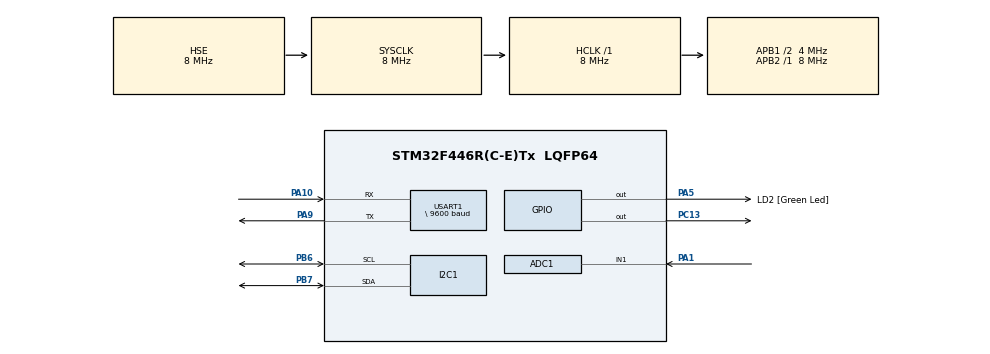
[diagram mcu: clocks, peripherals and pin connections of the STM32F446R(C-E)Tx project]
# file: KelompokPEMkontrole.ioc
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ADC1.Channel-0\#ChannelRegularConversion=ADC_CHANNEL_1
ADC1.NbrOfConversionFlag=1
ADC1.Rank-0\#ChannelRegularConversion=1
ADC1.SamplingTime-0\#ChannelRegularConversion=ADC_SAMPLETIME_3CYCLES
ADC1.master=1
FREERTOS.Tasks01=defaultTask,0,128,StartDefaultTask,Default,NULL,Dynamic,NULL,NULL;ReadPMTask,-2,128,StartTask02,Default,NULL,Dynamic,NULL,NULL;ReadMQTask,-2,128,StartTask03,Default,NULL,Dynamic,NULL,NULL;DisplayTask,0,128,StartTask04,Default,NULL,Dynamic,NULL,NULL
IWDG.Prescaler=IWDG_PRESCALER_64
Mcu.Family=STM32F4
Mcu.Name=STM32F446R(C-E)Tx
Mcu.Package=LQFP64
NVIC.PriorityGroup=NVIC_PRIORITYGROUP_4
NVIC.TIM2_IRQn=true\:15\:0\:false\:false\:true\:false\:false\:true\:true
NVIC.TimeBase=TIM2_IRQn
NVIC.TimeBaseIP=TIM2
PA1.Signal=ADCx_IN1
PA10.Mode=Asynchronous
PA10.Signal=USART1_RX
PA13.GPIO_Label=TMS
PA13.Mode=Serial_Wire
PA13.Signal=SYS_JTMS-SWDIO
PA14.GPIO_Label=TCK
PA14.Mode=Serial_Wire
PA14.Signal=SYS_JTCK-SWCLK
PA2.GPIO_Label=USART_TX
PA2.Signal=USART2_TX
PA3.GPIO_Label=USART_RX
PA3.Signal=USART2_RX
PA5.GPIO_Label=LD2 [Green Led]
PA5.Signal=GPIO_Output
PA9.Mode=Asynchronous
PA9.Signal=USART1_TX
PB3.GPIO_Label=SWO
PB3.Signal=SYS_JTDO-SWO
PB6.Mode=I2C
PB6.Signal=I2C1_SCL
PB7.Mode=I2C
PB7.Signal=I2C1_SDA
PC13.Signal=GPIO_Output
PC14-OSC32_IN.Mode=LSE-External-Oscillator
PC14-OSC32_IN.Signal=RCC_OSC32_IN
PC15-OSC32_OUT.Mode=LSE-External-Oscillator
PC15-OSC32_OUT.Signal=RCC_OSC32_OUT
PH0-OSC_IN.Mode=HSE-External-Oscillator
PH0-OSC_IN.Signal=RCC_OSC_IN
PH1-OSC_OUT.Mode=HSE-External-Oscillator
PH1-OSC_OUT.Signal=RCC_OSC_OUT
ProjectManager.HeapSize=0x200
ProjectManager.StackSize=0x400
ProjectManager.TargetToolchain=MDK-ARM V5.32
RCC.48MHZClocksFreq_Value=84000000
RCC.AHBFreq_Value=8000000
RCC.APB1CLKDivider=RCC_HCLK_DIV2
RCC.APB1Freq_Value=4000000
RCC.APB1TimFreq_Value=8000000
RCC.APB2Freq_Value=8000000
RCC.APB2TimFreq_Value=8000000
RCC.CortexFreq_Value=8000000
RCC.FLatency-AdvancedSettings=FLASH_LATENCY_0
RCC.HCLKFreq_Value=8000000
RCC.HSE_VALUE=8000000
RCC.HSI_VALUE=16000000
RCC.PLLM=4
RCC.PLLN=72
RCC.PLLSourceVirtual=RCC_PLLSOURCE_HSE
RCC.SYSCLKFreq_VALUE=8000000
RCC.SYSCLKSource=RCC_SYSCLKSOURCE_HSE
RCC.USBFreq_Value=72000000
RCC.VCOOutputFreq_Value=144000000
SH.ADCx_IN1.0=ADC1_IN1,IN1
TIM1.Prescaler=71
USART1.BaudRate=\ 9600
USART1.VirtualMode=VM_ASYNC
VP_FREERTOS_VS_CMSIS_V1.Mode=CMSIS_V1
VP_IWDG_VS_IWDG.Mode=IWDG_Activate
VP_SYS_VS_tim2.Mode=TIM2
VP_TIM1_VS_ClockSourceINT.Mode=Internal
board=NUCLEO-F446RE

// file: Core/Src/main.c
/* USER CODE BEGIN Header */
/**
  ******************************************************************************
  * @file           : main.c
  * @brief          : Main program body
  ******************************************************************************
  * @attention
  *
  * Copyright (c) 2025 STMicroelectronics.
  * All rights reserved.
  *
  * This software is licensed under terms that can be found in the LICENSE file
  * in the root directory of this software component.
  * If no LICENSE file comes with this software, it is provided AS-IS.
  *
  ******************************************************************************
  */
/* USER CODE END Header */
#include "main.h"
#include "cmsis_os.h"

/* USER CODE BEGIN Includes */
#include "pm25sensor.h"
#include "mq135_sensor.h"
#include "display1.h"
#include <string.h>
/* USER CODE END Includes */

ADC_HandleTypeDef hadc1;

I2C_HandleTypeDef hi2c1;

IWDG_HandleTypeDef hiwdg;

TIM_HandleTypeDef htim1;

UART_HandleTypeDef huart1;

osThreadId defaultTaskHandle;
osThreadId ReadPMTaskHandle;
osThreadId ReadMQTaskHandle;
osThreadId DisplayTaskHandle;

void SystemClock_Config(void);
static void MX_GPIO_Init(void);
static void MX_ADC1_Init(void);
static void MX_I2C1_Init(void);
static void MX_USART1_UART_Init(void);
static void MX_TIM1_Init(void);
static void MX_IWDG_Init(void);
void StartDefaultTask(void const * argument);
void StartTask02(void const * argument);
void StartTask03(void const * argument);
void StartTask04(void const * argument);

int main(void)
{

  /* MCU Configuration--------------------------------------------------------*/

  /* Reset of all peripherals, Initializes the Flash interface and the Systick. */
  HAL_Init();

  /* Configure the system clock */
  SystemClock_Config();

  /* Initialize all configured peripherals */
  MX_GPIO_Init();
  MX_ADC1_Init();
  MX_I2C1_Init();
  MX_USART1_UART_Init();
  MX_TIM1_Init();
  MX_IWDG_Init();

  /* Create the thread(s) */
  /* definition and creation of defaultTask */
  osThreadDef(defaultTask, StartDefaultTask, osPriorityNormal, 0, 128);
  defaultTaskHandle = osThreadCreate(osThread(defaultTask), NULL);

  /* definition and creation of ReadPMTask */
  osThreadDef(ReadPMTask, StartTask02, osPriorityLow, 0, 128);
  ReadPMTaskHandle = osThreadCreate(osThread(ReadPMTask), NULL);

  /* definition and creation of ReadMQTask */
  osThreadDef(ReadMQTask, StartTask03, osPriorityLow, 0, 128);
  ReadMQTaskHandle = osThreadCreate(osThread(ReadMQTask), NULL);

  /* definition and creation of DisplayTask */
  osThreadDef(DisplayTask, StartTask04, osPriorityNormal, 0, 128);
  DisplayTaskHandle = osThreadCreate(osThread(DisplayTask), NULL);

  /* Start scheduler */
  osKernelStart();

  /* We should never get here as control is now taken by the scheduler */

  /* Infinite loop */
  while (1)
  {

  }
}

void SystemClock_Config(void)
{
  RCC_OscInitTypeDef RCC_OscInitStruct = {0};
  RCC_ClkInitTypeDef RCC_ClkInitStruct = {0};

  /** Configure the main internal regulator output voltage
  */
  __HAL_RCC_PWR_CLK_ENABLE();
  __HAL_PWR_VOLTAGESCALING_CONFIG(PWR_REGULATOR_VOLTAGE_SCALE3);

  /** Initializes the RCC Oscillators according to the specified parameters
  * in the RCC_OscInitTypeDef structure.
  */
  RCC_OscInitStruct.OscillatorType = RCC_OSCILLATORTYPE_LSI|RCC_OSCILLATORTYPE_HSE;
  RCC_OscInitStruct.HSEState = RCC_HSE_ON;
  RCC_OscInitStruct.LSIState = RCC_LSI_ON;
  RCC_OscInitStruct.PLL.PLLState = RCC_PLL_NONE;
  if (HAL_RCC_OscConfig(&RCC_OscInitStruct) != HAL_OK)
  {
    Error_Handler();
  }

  /** Initializes the CPU, AHB and APB buses clocks
  */
  RCC_ClkInitStruct.ClockType = RCC_CLOCKTYPE_HCLK|RCC_CLOCKTYPE_SYSCLK
                              |RCC_CLOCKTYPE_PCLK1|RCC_CLOCKTYPE_PCLK2;
  RCC_ClkInitStruct.SYSCLKSource = RCC_SYSCLKSOURCE_HSE;
  RCC_ClkInitStruct.AHBCLKDivider = RCC_SYSCLK_DIV1;
  RCC_ClkInitStruct.APB1CLKDivider = RCC_HCLK_DIV2;
  RCC_ClkInitStruct.APB2CLKDivider = RCC_HCLK_DIV1;

  if (HAL_RCC_ClockConfig(&RCC_ClkInitStruct, FLASH_LATENCY_0) != HAL_OK)
  {
    Error_Handler();
  }
}

static void MX_ADC1_Init(void)
{

  ADC_ChannelConfTypeDef sConfig = {0};

  /** Configure the global features of the ADC (Clock, Resolution, Data Alignment and number of conversion)
  */
  hadc1.Instance = ADC1;
  hadc1.Init.ClockPrescaler = ADC_CLOCK_SYNC_PCLK_DIV2;
  hadc1.Init.Resolution = ADC_RESOLUTION_12B;
  hadc1.Init.ScanConvMode = DISABLE;
  hadc1.Init.ContinuousConvMode = DISABLE;
  hadc1.Init.DiscontinuousConvMode = DISABLE;
  hadc1.Init.ExternalTrigConvEdge = ADC_EXTERNALTRIGCONVEDGE_NONE;
  hadc1.Init.ExternalTrigConv = ADC_SOFTWARE_START;
  hadc1.Init.DataAlign = ADC_DATAALIGN_RIGHT;
  hadc1.Init.NbrOfConversion = 1;
  hadc1.Init.DMAContinuousRequests = DISABLE;
  hadc1.Init.EOCSelection = ADC_EOC_SINGLE_CONV;
  if (HAL_ADC_Init(&hadc1) != HAL_OK)
  {
    Error_Handler();
  }

  /** Configure for the selected ADC regular channel its corresponding rank in the sequencer and its sample time.
  */
  sConfig.Channel = ADC_CHANNEL_1;
  sConfig.Rank = 1;
  sConfig.SamplingTime = ADC_SAMPLETIME_3CYCLES;
  if (HAL_ADC_ConfigChannel(&hadc1, &sConfig) != HAL_OK)
  {
    Error_Handler();
  }

}

static void MX_I2C1_Init(void)
{

  hi2c1.Instance = I2C1;
  hi2c1.Init.ClockSpeed = 100000;
  hi2c1.Init.DutyCycle = I2C_DUTYCYCLE_2;
  hi2c1.Init.OwnAddress1 = 0;
  hi2c1.Init.AddressingMode = I2C_ADDRESSINGMODE_7BIT;
  hi2c1.Init.DualAddressMode = I2C_DUALADDRESS_DISABLE;
  hi2c1.Init.OwnAddress2 = 0;
  hi2c1.Init.GeneralCallMode = I2C_GENERALCALL_DISABLE;
  hi2c1.Init.NoStretchMode = I2C_NOSTRETCH_DISABLE;
  if (HAL_I2C_Init(&hi2c1) != HAL_OK)
  {
    Error_Handler();
  }

}

static void MX_IWDG_Init(void)
{

  hiwdg.Instance = IWDG;
  hiwdg.Init.Prescaler = IWDG_PRESCALER_64;
  hiwdg.Init.Reload = 4095;
  if (HAL_IWDG_Init(&hiwdg) != HAL_OK)
  {
    Error_Handler();
  }

}

static void MX_TIM1_Init(void)
{

  TIM_ClockConfigTypeDef sClockSourceConfig = {0};
  TIM_MasterConfigTypeDef sMasterConfig = {0};

  htim1.Instance = TIM1;
  htim1.Init.Prescaler = 71;
  htim1.Init.CounterMode = TIM_COUNTERMODE_UP;
  htim1.Init.Period = 65535;
  htim1.Init.ClockDivision = TIM_CLOCKDIVISION_DIV1;
  htim1.Init.RepetitionCounter = 0;
  htim1.Init.AutoReloadPreload = TIM_AUTORELOAD_PRELOAD_DISABLE;
  if (HAL_TIM_Base_Init(&htim1) != HAL_OK)
  {
    Error_Handler();
  }
  sClockSourceConfig.ClockSource = TIM_CLOCKSOURCE_INTERNAL;
  if (HAL_TIM_ConfigClockSource(&htim1, &sClockSourceConfig) != HAL_OK)
  {
    Error_Handler();
  }
  sMasterConfig.MasterOutputTrigger = TIM_TRGO_RESET;
  sMasterConfig.MasterSlaveMode = TIM_MASTERSLAVEMODE_DISABLE;
  if (HAL_TIMEx_MasterConfigSynchronization(&htim1, &sMasterConfig) != HAL_OK)
  {
    Error_Handler();
  }

}

static void MX_USART1_UART_Init(void)
{

  huart1.Instance = USART1;
  huart1.Init.BaudRate = 9600;
  huart1.Init.WordLength = UART_WORDLENGTH_8B;
  huart1.Init.StopBits = UART_STOPBITS_1;
  huart1.Init.Parity = UART_PARITY_NONE;
  huart1.Init.Mode = UART_MODE_TX_RX;
  huart1.Init.HwFlowCtl = UART_HWCONTROL_NONE;
  huart1.Init.OverSampling = UART_OVERSAMPLING_16;
  if (HAL_UART_Init(&huart1) != HAL_OK)
  {
    Error_Handler();
  }

}

static void MX_GPIO_Init(void)
{
  GPIO_InitTypeDef GPIO_InitStruct = {0};

  /* GPIO Ports Clock Enable */
  __HAL_RCC_GPIOC_CLK_ENABLE();
  __HAL_RCC_GPIOH_CLK_ENABLE();
  __HAL_RCC_GPIOA_CLK_ENABLE();
  __HAL_RCC_GPIOB_CLK_ENABLE();

  /*Configure GPIO pin Output Level */
  HAL_GPIO_WritePin(GPIOC, GPIO_PIN_13, GPIO_PIN_RESET);

  /*Configure GPIO pin Output Level */
  HAL_GPIO_WritePin(LD2_GPIO_Port, LD2_Pin, GPIO_PIN_RESET);

  /*Configure GPIO pin : PC13 */
  GPIO_InitStruct.Pin = GPIO_PIN_13;
  GPIO_InitStruct.Mode = GPIO_MODE_OUTPUT_PP;
  GPIO_InitStruct.Pull = GPIO_NOPULL;
  GPIO_InitStruct.Speed = GPIO_SPEED_FREQ_LOW;
  HAL_GPIO_Init(GPIOC, &GPIO_InitStruct);

  /*Configure GPIO pins : USART_TX_Pin USART_RX_Pin */
  GPIO_InitStruct.Pin = USART_TX_Pin|USART_RX_Pin;
  GPIO_InitStruct.Mode = GPIO_MODE_AF_PP;
  GPIO_InitStruct.Pull = GPIO_NOPULL;
  GPIO_InitStruct.Speed = GPIO_SPEED_FREQ_VERY_HIGH;
  GPIO_InitStruct.Alternate = GPIO_AF7_USART2;
  HAL_GPIO_Init(GPIOA, &GPIO_InitStruct);

  /*Configure GPIO pin : LD2_Pin */
  GPIO_InitStruct.Pin = LD2_Pin;
  GPIO_InitStruct.Mode = GPIO_MODE_OUTPUT_PP;
  GPIO_InitStruct.Pull = GPIO_NOPULL;
  GPIO_InitStruct.Speed = GPIO_SPEED_FREQ_LOW;
  HAL_GPIO_Init(LD2_GPIO_Port, &GPIO_InitStruct);

}

void StartDefaultTask(void const * argument)
{
  for(;;)
  {
    osDelay(1);
  }
}

void StartTask02(void const * argument)
{
  for(;;)
  {
    osDelay(1);
  }
}

void StartTask03(void const * argument)
{
  for(;;)
  {
    osDelay(1);
  }
}

void StartTask04(void const * argument)
{
  for(;;)
  {
    osDelay(1);
  }
}

void HAL_TIM_PeriodElapsedCallback(TIM_HandleTypeDef *htim)
{
  if (htim->Instance == TIM2) {
    HAL_IncTick();
  }
}

void Error_Handler(void)
{
  /* USER CODE BEGIN Error_Handler_Debug */
  /* User can add his own implementation to report the HAL error return state */
  __disable_irq();
  while (1)
  {
		HAL_GPIO_TogglePin(GPIOC, GPIO_PIN_13); // Blink error LED
    HAL_Delay(500);
  }
  /* USER CODE END Error_Handler_Debug */
}
